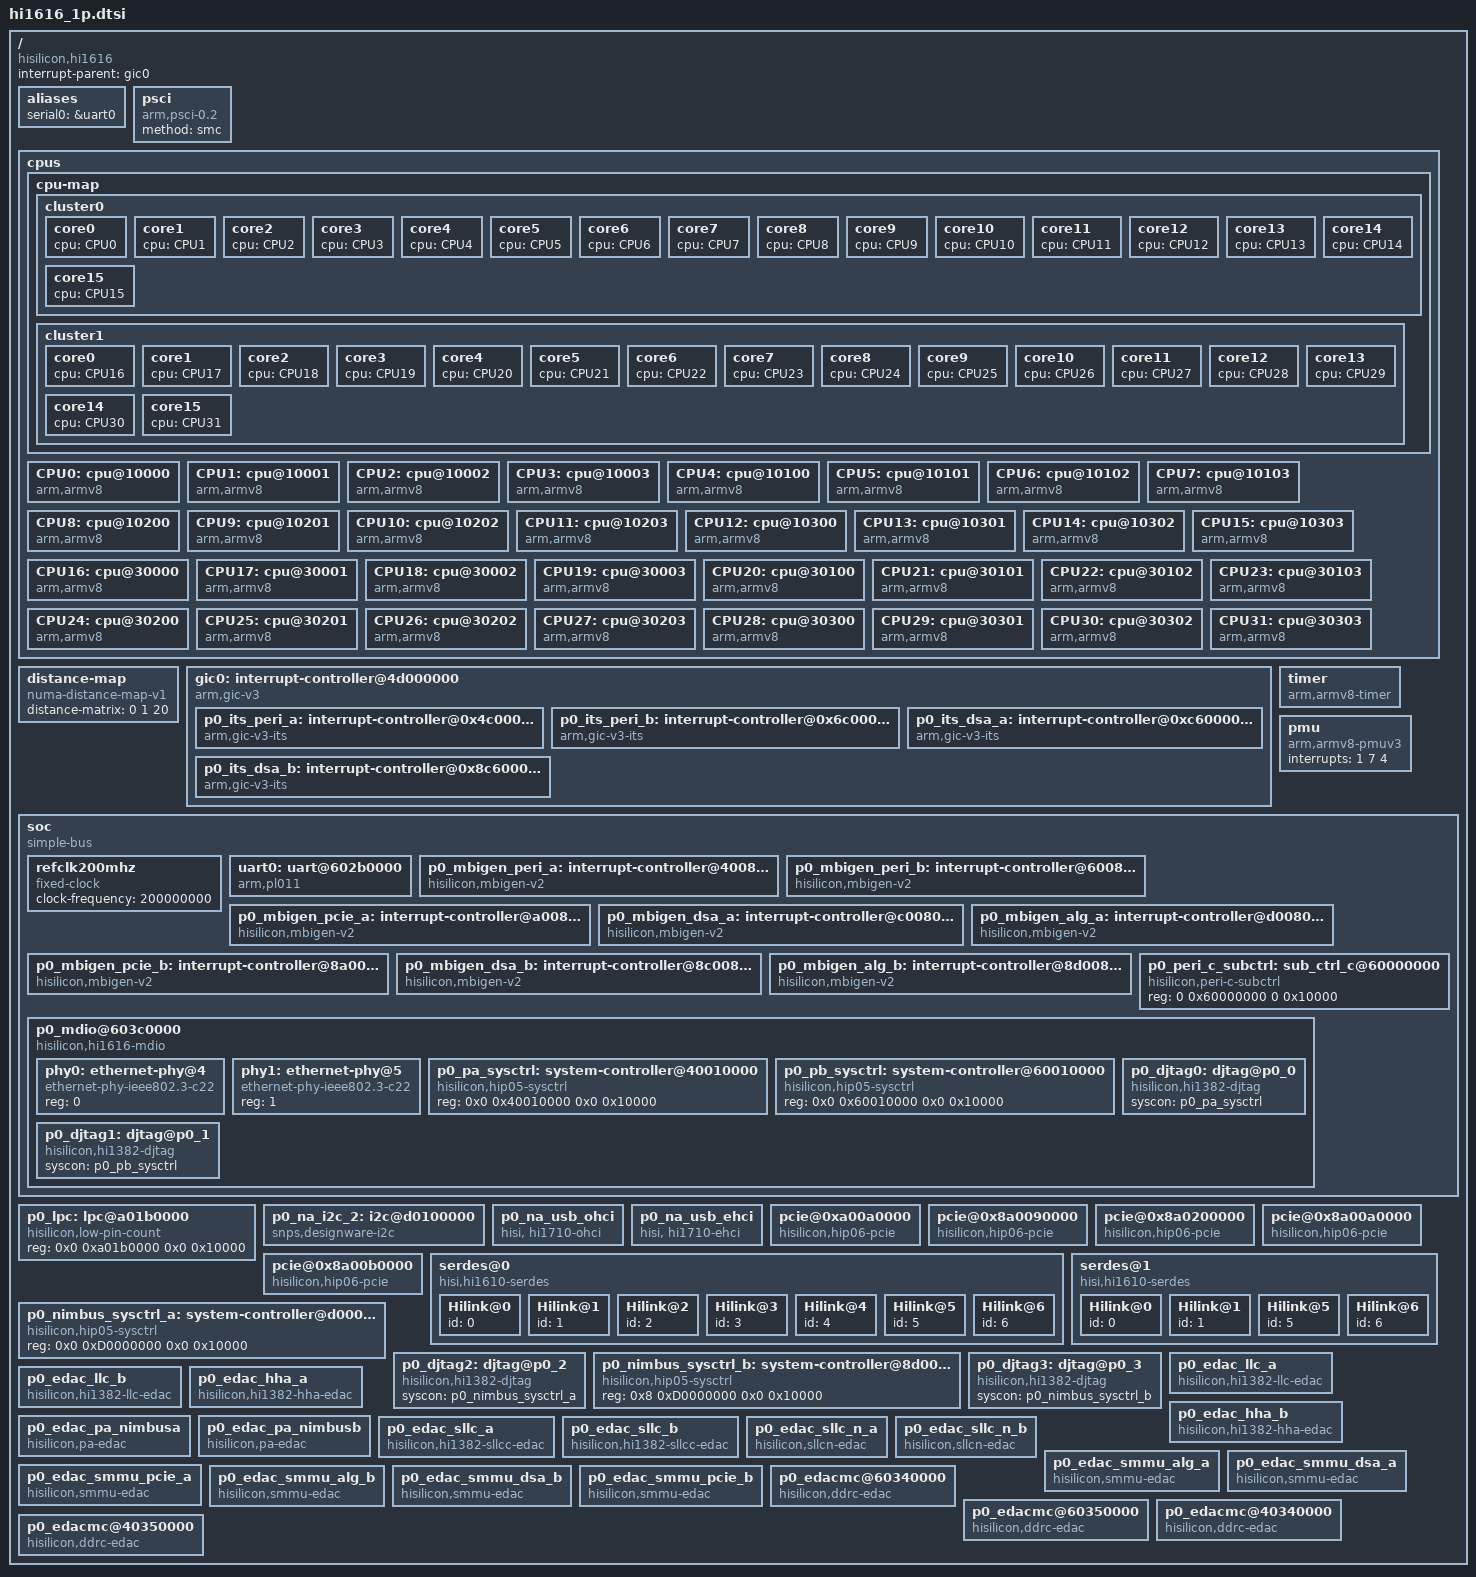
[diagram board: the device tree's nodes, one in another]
/**
 * dtsi file for Hisilicon Hi1616 Product Board
 *
 * Copyright (C) 2016 Hisilicon Ltd.
 *
 * This program is free software; you can redistribute it and/or modify
 * it under the terms of the GNU General Public License version 2 as
 * publishhed by the Free Software Foundation.
 *
 */

/ {
	#address-cells = <2>;
	#size-cells = <2>;
	compatible = "hisilicon,hi1616";
	interrupt-parent = <&gic0>;

	aliases {
		serial0 = &uart0;
	};


	psci {
		compatible = "arm,psci-0.2";
		method = "smc";
	};

	cpus {
		#address-cells = <1>;
		#size-cells = <0>;

		cpu-map {
			cluster0 {
				core0 {
					cpu = <&CPU0>;
				};

				core1 {
					cpu = <&CPU1>;
				};

				core2 {
					cpu = <&CPU2>;
				};

				core3 {
					cpu = <&CPU3>;
				};

				core4 {
					cpu = <&CPU4>;
				};

				core5 {
					cpu = <&CPU5>;
				};

				core6 {
					cpu = <&CPU6>;
				};

				core7 {
					cpu = <&CPU7>;
				};

				core8 {
					cpu = <&CPU8>;
				};

				core9 {
					cpu = <&CPU9>;
				};

				core10 {
					cpu = <&CPU10>;
				};

				core11 {
					cpu = <&CPU11>;
				};

				core12 {
					cpu = <&CPU12>;
				};

				core13 {
					cpu = <&CPU13>;
				};

				core14 {
					cpu = <&CPU14>;
				};

				core15 {
					cpu = <&CPU15>;
				};
			};

			cluster1 {
				core0 {
					cpu = <&CPU16>;
				};

				core1 {
					cpu = <&CPU17>;
				};

				core2 {
					cpu = <&CPU18>;
				};

				core3 {
					cpu = <&CPU19>;
				};

				core4 {
					cpu = <&CPU20>;
				};

				core5 {
					cpu = <&CPU21>;
				};

				core6 {
					cpu = <&CPU22>;
				};

				core7 {
					cpu = <&CPU23>;
				};

				core8 {
					cpu = <&CPU24>;
				};

				core9 {
					cpu = <&CPU25>;
				};

				core10 {
					cpu = <&CPU26>;
				};

				core11 {
					cpu = <&CPU27>;
				};

				core12 {
					cpu = <&CPU28>;
				};

				core13 {
					cpu = <&CPU29>;
				};

				core14 {
					cpu = <&CPU30>;
				};

				core15 {
					cpu = <&CPU31>;
				};
			};
		};

		CPU0: cpu@10000 {
			device_type = "cpu";
			compatible = "arm,armv8";
			reg = <0x10000>;
			enable-method = "psci";
			numa-node-id = <0>;
		};

		CPU1: cpu@10001 {
			device_type = "cpu";
			compatible = "arm,armv8";
			reg = <0x10001>;
			enable-method = "psci";
			numa-node-id = <0>;
		};

		CPU2: cpu@10002 {
			device_type = "cpu";
			compatible = "arm,armv8";
			reg = <0x10002>;
			enable-method = "psci";
			numa-node-id = <0>;
		};

		CPU3: cpu@10003 {
			device_type = "cpu";
			compatible = "arm,armv8";
			reg = <0x10003>;
			enable-method = "psci";
			numa-node-id = <0>;
		};

		CPU4: cpu@10100 {
			device_type = "cpu";
			compatible = "arm,armv8";
			reg = <0x10100>;
			enable-method = "psci";
			numa-node-id = <0>;
		};

		CPU5: cpu@10101 {
			device_type = "cpu";
			compatible = "arm,armv8";
			reg = <0x10101>;
			enable-method = "psci";
			numa-node-id = <0>;
		};

		CPU6: cpu@10102 {
			device_type = "cpu";
			compatible = "arm,armv8";
			reg = <0x10102>;
			enable-method = "psci";
			numa-node-id = <0>;
		};

		CPU7: cpu@10103 {
			device_type = "cpu";
			compatible = "arm,armv8";
			reg = <0x10103>;
			enable-method = "psci";
			numa-node-id = <0>;
		};

		CPU8: cpu@10200 {
			device_type = "cpu";
			compatible = "arm,armv8";
			reg = <0x10200>;
			enable-method = "psci";
			numa-node-id = <0>;
		};

		CPU9: cpu@10201 {
			device_type = "cpu";
			compatible = "arm,armv8";
			reg = <0x10201>;
			enable-method = "psci";
			numa-node-id = <0>;
		};

		CPU10: cpu@10202 {
			device_type = "cpu";
			compatible = "arm,armv8";
			reg = <0x10202>;
			enable-method = "psci";
			numa-node-id = <0>;
		};

		CPU11: cpu@10203 {
			device_type = "cpu";
			compatible = "arm,armv8";
			reg = <0x10203>;
			enable-method = "psci";
			numa-node-id = <0>;
		};

		CPU12: cpu@10300 {
			device_type = "cpu";
			compatible = "arm,armv8";
			reg = <0x10300>;
			enable-method = "psci";
			numa-node-id = <0>;
		};

		CPU13: cpu@10301 {
			device_type = "cpu";
			compatible = "arm,armv8";
			reg = <0x10301>;
			enable-method = "psci";
			numa-node-id = <0>;
		};

		CPU14: cpu@10302 {
			device_type = "cpu";
			compatible = "arm,armv8";
			reg = <0x10302>;
			enable-method = "psci";
			numa-node-id = <0>;
		};

		CPU15: cpu@10303 {
			device_type = "cpu";
			compatible = "arm,armv8";
			reg = <0x10303>;
			enable-method = "psci";
			numa-node-id = <0>;
		};

		CPU16: cpu@30000 {
			device_type = "cpu";
			compatible = "arm,armv8";
			reg = <0x30000>;
			enable-method = "psci";
			numa-node-id = <1>;
		};

		CPU17: cpu@30001 {
			device_type = "cpu";
			compatible = "arm,armv8";
			reg = <0x30001>;
			enable-method = "psci";
			numa-node-id = <1>;
		};

		CPU18: cpu@30002 {
			device_type = "cpu";
			compatible = "arm,armv8";
			reg = <0x30002>;
			enable-method = "psci";
			numa-node-id = <1>;
		};

		CPU19: cpu@30003 {
			device_type = "cpu";
			compatible = "arm,armv8";
			reg = <0x30003>;
			enable-method = "psci";
			numa-node-id = <1>;
		};

		CPU20: cpu@30100 {
			device_type = "cpu";
			compatible = "arm,armv8";
			reg = <0x30100>;
			enable-method = "psci";
			numa-node-id = <1>;
		};

		CPU21: cpu@30101 {
			device_type = "cpu";
			compatible = "arm,armv8";
			reg = <0x30101>;
			enable-method = "psci";
			numa-node-id = <1>;
		};

		CPU22: cpu@30102 {
			device_type = "cpu";
			compatible = "arm,armv8";
			reg = <0x30102>;
			enable-method = "psci";
			numa-node-id = <1>;
		};

		CPU23: cpu@30103 {
			device_type = "cpu";
			compatible = "arm,armv8";
			reg = <0x30103>;
			enable-method = "psci";
			numa-node-id = <1>;
		};

		CPU24: cpu@30200 {
			device_type = "cpu";
			compatible = "arm,armv8";
			reg = <0x30200>;
			enable-method = "psci";
			numa-node-id = <1>;
		};

		CPU25: cpu@30201 {
			device_type = "cpu";
			compatible = "arm,armv8";
			reg = <0x30201>;
			enable-method = "psci";
			numa-node-id = <1>;
		};

		CPU26: cpu@30202 {
			device_type = "cpu";
			compatible = "arm,armv8";
			reg = <0x30202>;
			enable-method = "psci";
			numa-node-id = <1>;
		};

		CPU27: cpu@30203 {
			device_type = "cpu";
			compatible = "arm,armv8";
			reg = <0x30203>;
			enable-method = "psci";
			numa-node-id = <1>;
		};

		CPU28: cpu@30300 {
			device_type = "cpu";
			compatible = "arm,armv8";
			reg = <0x30300>;
			enable-method = "psci";
			numa-node-id = <1>;
		};

		CPU29: cpu@30301 {
			device_type = "cpu";
			compatible = "arm,armv8";
			reg = <0x30301>;
			enable-method = "psci";
			numa-node-id = <1>;
		};

		CPU30: cpu@30302 {
			device_type = "cpu";
			compatible = "arm,armv8";
			reg = <0x30302>;
			enable-method = "psci";
			numa-node-id = <1>;
		};

		CPU31: cpu@30303 {
			device_type = "cpu";
			compatible = "arm,armv8";
			reg = <0x30303>;
			enable-method = "psci";
			numa-node-id = <1>;
		};
	};

	distance-map {
		compatible = "numa-distance-map-v1";
		distance-matrix = <0 1 20>;
	};

	gic0: interrupt-controller@4d000000 {
		compatible = "arm,gic-v3";
		#interrupt-cells = <3>;
		#address-cells = <2>;
		#size-cells = <2>;
		ranges;
		status-clear-fixup;
		interrupt-controller;
		#redistributor-regions = <2>;
		redistributor-stride = <0x0 0x40000>;
		reg = <0x0 0x4d000000 0x0 0x10000>,	/* P0 GICD A*/
		      <0x0 0x4d100000 0x0 0x400000>,	/* P0 GICR A*/
		      <0x0 0x6d100000 0x0 0x400000>,	/* P0 GICR B*/
		      <0x0 0xfe000000 0x0 0x10000>,	/* GICC */
		      <0x0 0xfe010000 0x0 0x10000>,     /* GICH */
		      <0x0 0xfe020000 0x0 0x10000>;     /* GICV */
		interrupts = <1 9 0xff04>;

		p0_its_peri_a: interrupt-controller@0x4c000000 {
			compatible = "arm,gic-v3-its";
			msi-controller;
			reg = <0x0 0x4c000000 0x0 0x1000000>;
		};

		p0_its_peri_b: interrupt-controller@0x6c000000 {
			compatible = "arm,gic-v3-its";
			msi-controller;
			reg = <0x0 0x6c000000 0x0 0x1000000>;
		};

		p0_its_dsa_a: interrupt-controller@0xc6000000 {
			compatible = "arm,gic-v3-its";
			msi-controller;
			reg = <0x0 0xc6000000 0x0 0x1000000>;
		};

		p0_its_dsa_b: interrupt-controller@0x8c6000000 {
			compatible = "arm,gic-v3-its";
			msi-controller;
			reg = <0x8 0xc6000000 0x0 0x1000000>;
		};
	};

	timer {
		compatible = "arm,armv8-timer";
		interrupts = <1 13 4>,
			     <1 14 4>,
			     <1 11 4>,
			     <1 10 4>;
		hisi,erratum-totem-v2;
	};

	pmu {
		compatible = "arm,armv8-pmuv3";
		interrupts = <1 7 4>;
	};

	soc {
		compatible = "simple-bus";
		#address-cells = <2>;
		#size-cells = <2>;
		ranges;

		refclk200mhz: refclk200mhz {
			compatible = "fixed-clock";
			#clock-cells = <0>;
			clock-frequency = <200000000>;
		};

		uart0: uart@602b0000 {
			compatible = "arm,pl011", "arm,primecell";
			reg = <0x0 0x602b0000 0x0 0x1000>;
			interrupt-parent = <&p0_mbigen_peri_b>;
			interrupts = <0x120c7 1 103 6>;
			clocks = <&refclk200mhz>;
			clock-names = "apb_pclk";
		};

		p0_mbigen_peri_a: interrupt-controller@40080000 {
			compatible = "hisilicon,mbigen-v2";
			msi-parent = <&p0_its_peri_a>;
			interrupt-controller;
			#interrupt-cells = <0x4>;
			reg = <0x0 0x40080000 0x0 0x10000>;
		};

		p0_mbigen_peri_b: interrupt-controller@60080000 {
			compatible = "hisilicon,mbigen-v2";
			msi-parent = <&p0_its_peri_b>;
			interrupt-controller;
			#interrupt-cells = <0x4>;
			reg = <0x0 0x60080000 0x0 0x10000>;
		};

		p0_mbigen_pcie_a: interrupt-controller@a0080000 {
			compatible = "hisilicon,mbigen-v2";
			msi-parent = <&p0_its_dsa_a>;
			interrupt-controller;
			#interrupt-cells = <4>;
			reg = <0x0 0xa0080000 0x0 0x10000>;
		};

		p0_mbigen_dsa_a: interrupt-controller@c0080000 {
			compatible = "hisilicon,mbigen-v2";
			msi-parent = <&p0_its_dsa_a>;
			interrupt-controller;
			#interrupt-cells = <4>;
			reg = <0x0 0xc0080000 0x0 0x10000>;
		};

		p0_mbigen_alg_a: interrupt-controller@d0080000 {
			compatible = "hisilicon,mbigen-v2";
			msi-parent = <&p0_its_dsa_a>;
			interrupt-controller;
			#interrupt-cells = <4>;
			reg = <0x0 0xd0080000 0x0 0x10000>;
		};

		p0_mbigen_pcie_b: interrupt-controller@8a0080000 {
			compatible = "hisilicon,mbigen-v2";
			msi-parent = <&p0_its_dsa_b>;
			interrupt-controller;
			#interrupt-cells = <4>;
			reg = <0x8 0xa0080000 0x0 0x10000>;
		};

		p0_mbigen_dsa_b: interrupt-controller@8c0080000 {
			compatible = "hisilicon,mbigen-v2";
			msi-parent = <&p0_its_dsa_b>;
			interrupt-controller;
			#interrupt-cells = <4>;
			reg = <0x8 0xc0080000 0x0 0x10000>;
		};

		p0_mbigen_alg_b: interrupt-controller@8d0080000 {
			compatible = "hisilicon,mbigen-v2";
			msi-parent = <&p0_its_dsa_b>;
			interrupt-controller;
			#interrupt-cells = <4>;
			reg = <0x8 0xd0080000 0x0 0x10000>;
		};

		p0_peri_c_subctrl: sub_ctrl_c@60000000 {
			compatible = "hisilicon,peri-c-subctrl", "syscon";
			reg = <0 0x60000000 0 0x10000>;
		};

		p0_mdio@603c0000 {
			compatible = "hisilicon,hi1616-mdio";
			reg = <0x0 0x603c0000 0x0 0x1000>;
			subctrl_vbase = <&p0_peri_c_subctrl>;
			#address-cells = <0x1>;
			#size-cells = <0x0>;

			phy0: ethernet-phy@4 {
				compatible = "ethernet-phy-ieee802.3-c22";
				reg = <0>;
			};
			phy1: ethernet-phy@5 {
				compatible = "ethernet-phy-ieee802.3-c22";
				reg = <1>;
			};

		p0_pa_sysctrl: system-controller@40010000 {
			compatible = "hisilicon,hip05-sysctrl", "syscon";
			reg = <0x0 0x40010000 0x0 0x10000>;
		};

		p0_pb_sysctrl: system-controller@60010000 {
			compatible = "hisilicon,hip05-sysctrl", "syscon";
			reg = <0x0 0x60010000 0x0 0x10000>;
		};

		p0_djtag0: djtag@p0_0 {
			compatible = "hisilicon,hi1382-djtag";
			syscon = <&p0_pa_sysctrl>;
		};

		p0_djtag1: djtag@p0_1 {
			compatible = "hisilicon,hi1382-djtag";
			syscon = <&p0_pb_sysctrl>;
		};
		};
	};

	p0_lpc: lpc@a01b0000 {
		compatible = "hisilicon,low-pin-count";
		reg = <0x0 0xa01b0000 0x0 0x10000>;
	};

	p0_na_i2c_2: i2c@d0100000 {
		compatible = "snps,designware-i2c";
		reg = <0x0 0xd0100000 0 0x10000>;
		interrupt-parent = <&p0_mbigen_alg_a>;
		interrupts = <0x40B10 1 3 6>;
		clocks = <&refclk200mhz>;
		i2c-sda-falling-time-ns = <913>;
		i2c-scl-falling-time-ns = <303>;
		i2c-sda-hold-time-ns = <0x9c2>;
		clock-frequency = <100000>;
	};

	p0_na_usb_ohci {
		compatible = "hisi, hi1710-ohci", "generic-ohci";
		reg = <0x0 0xa7030000 0x0 0x10000>;
		interrupt-parent = <&p0_mbigen_pcie_a>;
		interrupts = <0x40080 2 64 5>;
		dma-coherent;
	};

	p0_na_usb_ehci {
		compatible = "hisi, hi1710-ehci", "generic-ehci";
		reg = <0x0 0xa7020000 0x0 0x10000>;
		interrupt-parent = <&p0_mbigen_pcie_a>;
		interrupts = <0x40080 2 65 5>;
		dma-coherent;
	};

	pcie@0xa00a0000 {
		compatible = "hisilicon,hip06-pcie", "snps,dw-pcie";
		reg = <0x0 0xa00a0000 0x0 0x10000>,
		      <0x0 0xa0000000 0x0 0x10000>,
		      <0x0 0xa00e0000 0x0 0x10000>,
		      <0x0 0xbe800000 0x0 0x800000>;
		reg-names = "rc_dbi", "subctrl", "pcs", "ecam-cfg";
		bus-range = <0xe8 0xef>;
		msi-parent = <&p0_its_dsa_a>;
		interrupt-parent = <&p0_mbigen_pcie_a>;
		interrupts = <0x40087 10 91 5>;
		interrupt-names = "aer";
		#interrupt-cells = <1>;
		interrupt-map-mask = <0xf800 0 0 7>;
		interrupt-map = <0x0 0 0 1 &p0_mbigen_pcie_a 0x40087 10 95 5
				 0x0 0 0 2 &p0_mbigen_pcie_a 0x40087 10 95 5
				 0x0 0 0 3 &p0_mbigen_pcie_a 0x40087 10 95 5
				 0x0 0 0 4 &p0_mbigen_pcie_a 0x40087 10 95 5>;
		#address-cells = <3>;
		#size-cells = <2>;
		device_type = "pci";
		dma-coherent;
		ranges = <0x02000000 0 0xb0000000 0x0 0xb0000000 0 0xe800000
			  0x01000000 0 0 0 0xbfff0000 0 0x10000>;
		num-lanes = <8>;
		port-id = <2>;
		linux,pci-domain = <2>;
		status = "ok";
	};

	pcie@0x8a0090000 {
		compatible = "hisilicon,hip06-pcie", "snps,dw-pcie";
		reg = <0x8 0xa0090000 0x0 0x10000>,
		      <0x8 0xa0000000 0x0 0x10000>,
		      <0x8 0xa00c0000 0x0 0x10000>,
		      <0x8 0xa8800000 0x0 0x800000>;
		reg-names = "rc_dbi", "subctrl", "pcs", "ecam-cfg";
		bus-range = <0x88 0x8f>;
		msi-parent = <&p0_its_dsa_b>;
		interrupt-parent = <&p0_mbigen_pcie_b>;
		interrupts = <0x42085 10 70 5>;
		interrupt-names = "aer";
		#interrupt-cells = <1>;
		interrupt-map-mask = <0xf800 0 0 7>;
		interrupt-map = <0x0 0 0 1 &p0_mbigen_pcie_b 0x42085 10 74 5
				 0x0 0 0 2 &p0_mbigen_pcie_b 0x42085 10 74 5
				 0x0 0 0 3 &p0_mbigen_pcie_b 0x42085 10 74 5
				 0x0 0 0 4 &p0_mbigen_pcie_b 0x42085 10 74 5>;
		#address-cells = <3>;
		#size-cells = <2>;
		device_type = "pci";
		dma-coherent;
		ranges = <0x02000000 0x0 0xa9000000 0x8 0xa9000000 0x0 0xff0000
			  0x01000000 0x0 0x0 0x8 0xa9ff0000 0x0 0x10000>;
		num-lanes = <8>;
		port-id = <0>;
		linux,pci-domain = <4>;
		status = "ok";
	};

	pcie@0x8a0200000 {
		compatible = "hisilicon,hip06-pcie", "snps,dw-pcie";
		reg = <0x8 0xa0200000 0x0 0x10000>,
		      <0x8 0xa0000000 0x0 0x10000>,
		      <0x8 0xa00d0000 0x0 0x10000>,
		      <0x8 0xb7000000 0x0 0x800000>;
		reg-names = "rc_dbi", "subctrl", "pcs", "ecam-cfg";
		bus-range = <0x70 0x77>;
		msi-parent = <&p0_its_dsa_b>;
		interrupt-parent = <&p0_mbigen_pcie_b>;
		interrupts = <0x42086 11 80 5>;
		interrupt-names = "aer";
		#interrupt-cells = <1>;
		interrupt-map-mask = <0xf800 0 0 7>;
		interrupt-map = <0x0 0 0 1 &p0_mbigen_pcie_b 0x42086 11 85 5
				 0x0 0 0 2 &p0_mbigen_pcie_b 0x42086 11 85 5
				 0x0 0 0 3 &p0_mbigen_pcie_b 0x42086 11 85 5
				 0x0 0 0 4 &p0_mbigen_pcie_b 0x42086 11 85 5>;
		#address-cells = <3>;
		#size-cells = <2>;
		device_type = "pci";
		dma-coherent;
		ranges = <0x02000000 0x0 0xb0000000 0x8 0xb0000000 0x0 0x7000000
			  0x01000000 0x0 0x0 0x8 0xb7ff0000 0x0 0x10000>;
		num-lanes = <8>;
		port-id = <1>;
		linux,pci-domain = <5>;
		status = "ok";
	};

	pcie@0x8a00a0000 {
		compatible = "hisilicon,hip06-pcie", "snps,dw-pcie";
		reg = <0x8 0xa00a0000 0x0 0x10000>,
		      <0x8 0xa0000000 0x0 0x10000>,
		      <0x8 0xa00e0000 0x0 0x10000>,
		      <0x8 0xb9000000 0x0 0x800000>;
		reg-names = "rc_dbi", "subctrl", "pcs", "ecam-cfg";
		bus-range = <0x90 0x97>;
		msi-parent = <&p0_its_dsa_b>;
		interrupt-parent = <&p0_mbigen_pcie_b>;
		interrupts = <0x42087 10 91 5>;
		interrupt-names = "aer";
		#interrupt-cells = <1>;
		interrupt-map-mask = <0xf800 0 0 7>;
		interrupt-map = <0x0 0 0 1 &p0_mbigen_pcie_b 0x42087 10 95 5
				 0x0 0 0 2 &p0_mbigen_pcie_b 0x42087 10 95 5
				 0x0 0 0 3 &p0_mbigen_pcie_b 0x42087 10 95 5
				 0x0 0 0 4 &p0_mbigen_pcie_b 0x42087 10 95 5>;
		#address-cells = <3>;
		#size-cells = <2>;
		device_type = "pci";
		dma-coherent;
		ranges = <0x02000000 0x0 0xb9800000 0x8 0xb9800000 0x0 0x6800000
			  0x01000000 0x0 0x0 0x8 0xb8000000 0x0 0x10000>;
		num-lanes = <1>;
		port-id = <2>;
		linux,pci-domain = <6>;
		status = "ok";
	};

	pcie@0x8a00b0000 {
		compatible = "hisilicon,hip06-pcie", "snps,dw-pcie";
		reg = <0x8 0xa00b0000 0x0 0x10000>,
		      <0x8 0xa0000000 0x0 0x10000>,
		      <0x8 0xa00f0000 0x0 0x10000>,
		      <0x8 0xaa000000 0x0 0x800000>;
		reg-names = "rc_dbi", "subctrl", "pcs", "ecam-cfg";
		bus-range = <0xa0 0xa7>;
		msi-parent = <&p0_its_dsa_b>;
		interrupt-parent = <&p0_mbigen_pcie_b>;
		interrupts = <0x42088 10 101 5>;
		interrupt-names = "aer";
		#interrupt-cells = <1>;
		interrupt-map-mask = <0xf800 0 0 7>;
		interrupt-map = <0x0 0 0 1 &p0_mbigen_pcie_b 0x42088 10 105 5
				 0x0 0 0 2 &p0_mbigen_pcie_b 0x42088 10 105 5
				 0x0 0 0 3 &p0_mbigen_pcie_b 0x42088 10 105 5
				 0x0 0 0 4 &p0_mbigen_pcie_b 0x42088 10 105 5>;
		#address-cells = <3>;
		#size-cells = <2>;
		device_type = "pci";
		dma-coherent;
		ranges = <0x02000000 0x0 0xaa800000 0x8 0xaa800000 0x0 0x57f0000
			  0x01000000 0x0 0x0 0x8 0xafff0000 0x0 0x10000>;
		num-lanes = <1>;
		port-id = <3>;
		linux,pci-domain = <7>;
		status = "ok";
	};

	serdes@0 {
		compatible = "hisi,hi1610-serdes";
		id =	<0>;
		reg =	<0x0 0xc0000000 0 0x10000>,
			<0x0 0xa0000000 0 0x10000>,
			<0x0 0xd0000000 0 0x10000>,
			<0x0 0xc2200000 0 0x40010>;
		reg-names =	"sas_dsaf_base",
				"sas_pcie_base",
				"alg_hccs_base",
				"hilink34_base";
		Hilink@0 {
			id = <0>;
		};
		Hilink@1 {
			id = <1>;
		};
		Hilink@2 {
			id = <2>;
		};
		Hilink@3 {
			id = <3>;
		};
		Hilink@4 {
			id = <4>;
		};
		Hilink@5 {
			id = <5>;
		};
		Hilink@6 {
			id = <6>;
		};
	};

	serdes@1 {
		compatible = "hisi,hi1610-serdes";
		id =	<1>;
		reg =	<0x8 0xc0000000 0 0x10000>,
			<0x8 0xa0000000 0 0x10000>,
			<0x8 0xd0000000 0 0x10000>;
		reg-names =	"sas_dsaf_base",
				"sas_pcie_base",
				"alg_hccs_base";
		Hilink@0 {
			id = <0>;
		};
		Hilink@1 {
			id = <1>;
		};
		Hilink@5 {
			id = <5>;
		};
		Hilink@6 {
			id = <6>;
		};
	};

	p0_nimbus_sysctrl_a: system-controller@d0000000 {
		compatible = "hisilicon,hip05-sysctrl", "syscon";
		reg = <0x0 0xD0000000 0x0 0x10000>;
	};

	p0_djtag2: djtag@p0_2 {
		compatible = "hisilicon,hi1382-djtag";
		syscon = <&p0_nimbus_sysctrl_a>;
	};

	p0_nimbus_sysctrl_b: system-controller@8d0000000 {
		compatible = "hisilicon,hip05-sysctrl", "syscon";
		reg = <0x8 0xD0000000 0x0 0x10000>;
	};

	p0_djtag3: djtag@p0_3 {
		compatible = "hisilicon,hi1382-djtag";
		syscon = <&p0_nimbus_sysctrl_b>;
	};

	p0_edac_llc_a {
		compatible = "hisilicon,hi1382-llc-edac";
		reg = <0x0 0x40080000 0x0 0x10000>;
		interrupt-parent = <&p0_mbigen_peri_a>;
		interrupts =	<0x120D0 17 0 7>,
				<0x120D0 17 1 7>,
				<0x120D0 17 2 7>,
				<0x120D0 17 2 7>,
				<0x120D0 17 4 7>,
				<0x120D0 17 5 7>,
				<0x120D0 17 6 7>,
				<0x120D0 17 7 7>,
				<0x120D0 17 8 7>,
				<0x120D0 17 9 7>,
				<0x120D0 17 10 7>,
				<0x120D0 17 11 7>,
				<0x120D0 17 12 7>,
				<0x120D0 17 13 7>,
				<0x120D0 17 14 7>,
				<0x120D0 17 15 7>,
				<0x120D0 17 16 7>;
		djtag = <&p0_djtag0>;
	};

	p0_edac_llc_b {
		compatible = "hisilicon,hi1382-llc-edac";
		reg = <0x0 0x60080000 0x0 0x10000>;
		interrupt-parent = <&p0_mbigen_peri_b>;
		interrupts =	<0x120D0 17 0 7>,
				<0x120D0 17 1 7>,
				<0x120D0 17 2 7>,
				<0x120D0 17 2 7>,
				<0x120D0 17 4 7>,
				<0x120D0 17 5 7>,
				<0x120D0 17 6 7>,
				<0x120D0 17 7 7>,
				<0x120D0 17 8 7>,
				<0x120D0 17 9 7>,
				<0x120D0 17 10 7>,
				<0x120D0 17 11 7>,
				<0x120D0 17 12 7>,
				<0x120D0 17 13 7>,
				<0x120D0 17 14 7>,
				<0x120D0 17 15 7>,
				<0x120D0 17 16 7>;
		djtag = <&p0_djtag1>;
	};

	p0_edac_hha_a {
		compatible = "hisilicon,hi1382-hha-edac";
		reg = <0x0 0x40080000 0x0 0x10000>;
		interrupt-parent = <&p0_mbigen_peri_a>;
		interrupts =	<0x120D0 13 0 7>,
				<0x120D0 13 1 7>,
				<0x120D0 13 2 7>,
				<0x120D0 13 2 7>,
				<0x120D0 13 4 7>,
				<0x120D0 13 5 7>,
				<0x120D0 13 6 7>,
				<0x120D0 13 7 7>,
				<0x120D0 13 8 7>,
				<0x120D0 13 9 7>,
				<0x120D0 13 10 7>,
				<0x120D0 13 11 7>,
				<0x120D0 13 12 7>;
		djtag = <&p0_djtag0>;
	};

	p0_edac_hha_b {
		compatible = "hisilicon,hi1382-hha-edac";
		reg = <0x0 0x60080000 0x0 0x10000>;
		interrupt-parent = <&p0_mbigen_peri_b>;
		interrupts =	<0x120D0 13 0 7>,
				<0x120D0 13 1 7>,
				<0x120D0 13 2 7>,
				<0x120D0 13 2 7>,
				<0x120D0 13 4 7>,
				<0x120D0 13 5 7>,
				<0x120D0 13 6 7>,
				<0x120D0 13 7 7>,
				<0x120D0 13 8 7>,
				<0x120D0 13 9 7>,
				<0x120D0 13 10 7>,
				<0x120D0 13 11 7>,
				<0x120D0 13 12 7>;
		djtag = <&p0_djtag1>;
	};

	p0_edac_pa_nimbusa {
		compatible = "hisilicon,pa-edac";
		reg = <0x0 0xD0000000 0x0 0x10000>;
		interrupt-parent = <&p0_mbigen_alg_a>;
		interrupts =	<0x40b1a 15 14 6>,
				<0x40b1a 15 15 6>,
				<0x40b1a 15 16 6>,
				<0x40b1a 15 17 6>,
				<0x40b1a 15 18 6>,
				<0x40b1a 15 19 6>,
				<0x40b1a 15 20 6>,
				<0x40b1a 15 21 6>,
				<0x40b1a 15 22 6>,
				<0x40b1a 15 23 6>,
				<0x40b1a 15 24 6>,
				<0x40b1a 15 25 6>,
				<0x40b1a 15 26 6>,
				<0x40b1a 15 27 6>,
				<0x40b1a 15 28 6>;
		djtag = <&p0_djtag2>;
	};

	p0_edac_pa_nimbusb {
		compatible = "hisilicon,pa-edac";
		reg = <0x8 0xD0000000 0x0 0x10000>;
		interrupt-parent = <&p0_mbigen_alg_b>;
		interrupts =	<0x42b1a 15 14 6>,
				<0x42b1a 15 15 6>,
				<0x42b1a 15 16 6>,
				<0x42b1a 15 17 6>,
				<0x42b1a 15 18 6>,
				<0x42b1a 15 19 6>,
				<0x42b1a 15 20 6>,
				<0x42b1a 15 21 6>,
				<0x42b1a 15 22 6>,
				<0x42b1a 15 23 6>,
				<0x42b1a 15 24 6>,
				<0x42b1a 15 25 6>,
				<0x42b1a 15 26 6>,
				<0x42b1a 15 27 6>,
				<0x42b1a 15 28 6>;
		djtag = <&p0_djtag3>;
	};

	p0_edac_sllc_a {
		compatible = "hisilicon,hi1382-sllcc-edac";
		reg = <0x0 0x40080000 0x0 0x10000>;
		interrupt-parent = <&p0_mbigen_peri_a>;
		interrupts =	<0x120D0 11 0 7>,
				<0x120D0 11 1 7>,
				<0x120D0 11 2 7>,
				<0x120D0 11 2 7>,
				<0x120D0 11 4 7>,
				<0x120D0 11 5 7>,
				<0x120D0 11 6 7>,
				<0x120D0 11 7 7>,
				<0x120D0 11 8 7>,
				<0x120D0 11 9 7>,
				<0x120D0 11 10 7>;
		djtag = <&p0_djtag0>;
	};

	p0_edac_sllc_b {
		compatible = "hisilicon,hi1382-sllcc-edac";
		reg = <0x0 0x60080000 0x0 0x10000>;
		interrupt-parent = <&p0_mbigen_peri_b>;
		interrupts =	<0x120D0 11 0 7>,
				<0x120D0 11 1 7>,
				<0x120D0 11 2 7>,
				<0x120D0 11 2 7>,
				<0x120D0 11 4 7>,
				<0x120D0 11 5 7>,
				<0x120D0 11 6 7>,
				<0x120D0 11 7 7>,
				<0x120D0 11 8 7>,
				<0x120D0 11 9 7>,
				<0x120D0 11 10 7>;
		djtag = <&p0_djtag1>;
	};

	p0_edac_sllc_n_a {
		compatible = "hisilicon,sllcn-edac";
		reg = <0x0 0xD0080000 0x0 0x10000>;
		interrupt-parent = <&p0_mbigen_alg_a>;
		interrupts =	<0x40b1a 15 14 6>,
				<0x40b1a 15 15 6>,
				<0x40b1a 15 16 6>,
				<0x40b1a 15 17 6>,
				<0x40b1a 15 18 6>,
				<0x40b1a 15 19 6>,
				<0x40b1a 15 20 6>,
				<0x40b1a 15 21 6>,
				<0x40b1a 15 22 6>,
				<0x40b1a 15 23 6>,
				<0x40b1a 15 24 6>,
				<0x40b1a 15 25 6>,
				<0x40b1a 15 26 6>,
				<0x40b1a 15 27 6>,
				<0x40b1a 15 28 6>;
		djtag = <&p0_djtag2>;
	};

	p0_edac_sllc_n_b {
		compatible = "hisilicon,sllcn-edac";
		reg = <0x8 0xD0080000 0x0 0x10000>;
		interrupt-parent = <&p0_mbigen_alg_b>;
		interrupts =	<0x42b1a 15 14 6>,
				<0x42b1a 15 15 6>,
				<0x42b1a 15 16 6>,
				<0x42b1a 15 17 6>,
				<0x42b1a 15 18 6>,
				<0x42b1a 15 19 6>,
				<0x42b1a 15 20 6>,
				<0x42b1a 15 21 6>,
				<0x42b1a 15 22 6>,
				<0x42b1a 15 23 6>,
				<0x42b1a 15 24 6>,
				<0x42b1a 15 25 6>,
				<0x42b1a 15 26 6>,
				<0x42b1a 15 27 6>,
				<0x42b1a 15 28 6>;
		djtag = <&p0_djtag3>;
	};

	p0_edac_smmu_alg_a {
		compatible = "hisilicon,smmu-edac";
		reg = <0x0 0xD0040000 0x0 0x20000>;
		interrupt-parent = <&p0_mbigen_alg_a>;
		interrupts =	<0x40b1b 3 29 6>,
				<0x40b1b 3 30 6>,
				<0x40b1b 3 31 6>;
	};

	p0_edac_smmu_dsa_a {
		compatible = "hisilicon,smmu-edac";
		reg = <0x0 0xC0040000 0x0 0x20000>;
		interrupt-parent = <&p0_mbigen_dsa_a>;
		interrupts =	<0x40b20 3 78 6>,
				<0x40b20 3 79 6>,
				<0x40b20 3 80 6>;
	};

	p0_edac_smmu_pcie_a {
		compatible = "hisilicon,smmu-edac";
		reg = <0x0 0xA0040000 0x0 0x20000>;
		interrupt-parent = <&p0_mbigen_pcie_a>;
		interrupts =	<0x40b0c 3 39 7>,
				<0x40b0c 3 40 7>,
				<0x40b0c 3 41 7>;
	};

	p0_edac_smmu_alg_b {
		compatible = "hisilicon,smmu-edac";
		reg = <0x8 0xD0040000 0x0 0x20000>;
		interrupt-parent = <&p0_mbigen_alg_b>;
		interrupts =	<0x42b1b 3 29 6>,
				<0x42b1b 3 30 6>,
				<0x42b1b 3 31 6>;
	};

	p0_edac_smmu_dsa_b {
		compatible = "hisilicon,smmu-edac";
		reg = <0x8 0xC0040000 0x0 0x20000>;
		interrupt-parent = <&p0_mbigen_dsa_b>;
		interrupts =	<0x42b20 3 78 6>,
				<0x42b20 3 79 6>,
				<0x42b20 3 80 6>;
	};

	p0_edac_smmu_pcie_b {
		compatible = "hisilicon,smmu-edac";
		reg = <0x8 0xA0040000 0x0 0x20000>;
		interrupt-parent = <&p0_mbigen_pcie_b>;
		interrupts =	<0x42b0c 3 39 7>,
				<0x42b0c 3 40 7>,
				<0x42b0c 3 41 7>;
	};

	p0_edacmc@60340000 {
		compatible = "hisilicon,ddrc-edac";
		reg = <0x0 0x60340000 0x0 0x10000>;
		interrupt-parent = <&p0_mbigen_peri_b>;
		interrupts =	<0x120ce 2 110 6>,
				<0x120ce 2 111 6>;
	};

	p0_edacmc@60350000 {
		compatible = "hisilicon,ddrc-edac";
		reg = <0x0 0x60350000 0x0 0x10000>;
		interrupt-parent = <&p0_mbigen_peri_b>;
		interrupts =	<0x121ce 2 113 6>,
				<0x121ce 2 114 6>;
	};

	p0_edacmc@40340000 {
		compatible = "hisilicon,ddrc-edac";
		reg = <0x0 0x40340000 0x0 0x10000>;
		interrupt-parent = <&p0_mbigen_peri_a>;
		interrupts =	<0x120ce 2 110 6>,
				<0x120ce 2 111 6>;
	};

	p0_edacmc@40350000 {
		compatible = "hisilicon,ddrc-edac";
		reg = <0x0 0x40350000 0x0 0x10000>;
		interrupt-parent = <&p0_mbigen_peri_a>;
		interrupts =	<0x121ce 2 113 6>,
				<0x121ce 2 114 6>;
	};

	/include/ "hi1616_sas_evb_p0_na.dtsi"
	/include/ "hi1616_sas_evb_p0_nb.dtsi"
	/include/ "hi1616_1p_hns.dtsi"
};
